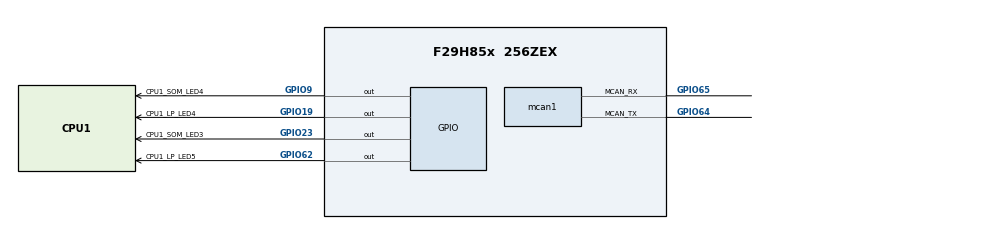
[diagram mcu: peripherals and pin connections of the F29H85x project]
/**
 * @cliArgs --device "F29H85x" --package "256ZEX" --part "F29H85x_256ZEX" --context "CPU1" --product "MCU_SDK_F29H85x@1.02.02.00"
 * @versions {"tool":"1.25.0+4237"}
 */

    
const divider15       = system.clockTree["PLL_REFDIV"];
divider15.divideValue = 1;

const multiplier1         = system.clockTree["PLL_IMULT"];
multiplier1.multiplyValue = 40;

const mux7       = system.clockTree["OSCCLKSRCSEL"];
mux7.inputSelect = "INTOSC2";

/**
 * Import the modules used in this configuration.
 */
const clocktree     = scripting.addModule("/driverlib/clocktree.js");
const cputimer      = scripting.addModule("/driverlib/cputimer.js", {}, false);
const cputimer2     = cputimer.addInstance();
const gpio          = scripting.addModule("/driverlib/gpio.js", {}, false);
const gpio1         = gpio.addInstance();
const gpio2         = gpio.addInstance();
const gpio3         = gpio.addInstance();
const gpio4         = gpio.addInstance();
const jtag          = scripting.addModule("/driverlib/jtag.js");
const mcan          = scripting.addModule("/driverlib/mcan.js", {}, false);
const mcan1         = mcan.addInstance();
const clock_c29_sdk = scripting.addModule("/kernel/dpl/clock_c29_sdk");

/**
 * Write custom configuration values to the imported modules.
 */
const divider4       = system.clockTree["EPWMCLKDIV"];
divider4.divideValue = 1;

const divider8       = system.clockTree["MCANACLKDIV"];
divider8.divideValue = 10;

cputimer2.$name              = "myCPUTIMER0";
cputimer2.timerPeriod        = 200000000;
cputimer2.startTimer         = true;
cputimer2.enableInterrupt    = true;
cputimer2.registerInterrupts = true;
cputimer2.periphClock.$name  = "driverlib_perClock0";

gpio1.direction       = "GPIO_DIR_MODE_OUT";
gpio1.$name           = "CPU1_SOM_LED4";
gpio1.gpioPin.$assign = "GPIO9";

gpio2.direction       = "GPIO_DIR_MODE_OUT";
gpio2.$name           = "CPU1_SOM_LED3";
gpio2.gpioPin.$assign = "GPIO23";

gpio3.$name           = "CPU1_LP_LED4";
gpio3.direction       = "GPIO_DIR_MODE_OUT";
gpio3.gpioPin.$assign = "GPIO19";

gpio4.$name           = "CPU1_LP_LED5";
gpio4.initialValue    = 1;
gpio4.direction       = "GPIO_DIR_MODE_OUT";
gpio4.gpioPin.$assign = "GPIO62";


mcan1.loopbackMode              = false;
mcan1.wkupReqEnable             = true;
mcan1.tdcEnable                 = true;
mcan1.autoWkupEnable            = true;
mcan1.wdcPreload                = 0;
mcan1.nomRatePrescalar          = 0;
mcan1.nomTimeSeg1               = 9;
mcan1.nomTimeSeg2               = 8;
mcan1.nomSynchJumpWidth         = 8;
mcan1.dataRatePrescalar         = 0;
mcan1.additionalCoreConfig      = true;
mcan1.txEventFIFOWaterMark      = 0;
mcan1.rxFIFO0waterMark          = 0;
mcan1.rxFIFO1waterMark          = 0;
mcan1.stdFilts                  = 1;
mcan1.$name                     = "SBL_MCANA";
mcan1.rrfe                      = true;
mcan1.rrfs                      = true;
mcan1.anfe                      = "1";
mcan1.anfs                      = "1";
mcan1.flesa                     = 128;
mcan1.txStartAddr               = 256;
mcan1.txBufNum                  = 8;
mcan1.txFIFOSize                = 24;
mcan1.txEventFIFOStartAddr      = 448;
mcan1.rxFIFO0startAddr          = 512;
mcan1.rxFIFO0size               = 32;
mcan1.rxFIFO1size               = 20;
mcan1.extFilts                  = 1;
mcan1.rxFIFO1startAddr          = 896;
mcan1.rxBufStartAddr            = 1280;
mcan1.enableInterrupt           = true;
mcan1.registerInterruptLine0    = true;
mcan1.interruptFlags            = ["MCAN_IR_RF0N_MASK"];
mcan1.interruptLine0Flag        = ["MCAN_IR_RF0N_MASK"];
mcan1.txEventFIFOSize           = 0;
mcan1.interruptLine             = ["MCAN_INTR_LINE_NUM_0"];
mcan1.mcan.$assign              = "MCANA";
mcan1.mcan.mcan_rxPin.$assign   = "GPIO65";
mcan1.mcan.mcan_txPin.$assign   = "GPIO64";
mcan1.periphClock.$name         = "driverlib_perClock4";
mcan1.periphConfig.$name        = "driverlib_perConfig2";
mcan1.stdFilt0.$name            = "stdFilt0";
mcan1.stdFilt0.sfid2            = 15;
mcan1.stdFilt0.sfec             = "MCAN_STDFILTEC_FIFO0";
mcan1.extFilt0.$name            = "extFilt0";
mcan1.extFilt0.efec             = "MCAN_EXTFILTEC_FIFO0";
mcan1.extFilt0.efid2            = 15;
mcan1.mcanInt0.interruptHandler = "SBL_mcanNotifyISR";

clock_c29_sdk.dplTimer.periphClock.$name                  = "driverlib_perClock1";
clock_c29_sdk.dplTimer.periphClock.pinmuxPeripheralModule = scripting.forceWrite("");

/**
 * Pinmux solution for unlocked pins/peripherals. This ensures that minor changes to the automatic solver in a future
 * version of the tool will not impact the pinmux you originally saw.  These lines can be completely deleted in order to
 * re-solve from scratch.
 */
jtag.JTAG.$suggestSolution        = "JTAG";
jtag.JTAG.tdoPin.$suggestSolution = "GPIO223/TDO";
jtag.JTAG.tdiPin.$suggestSolution = "GPIO222/TDI";
